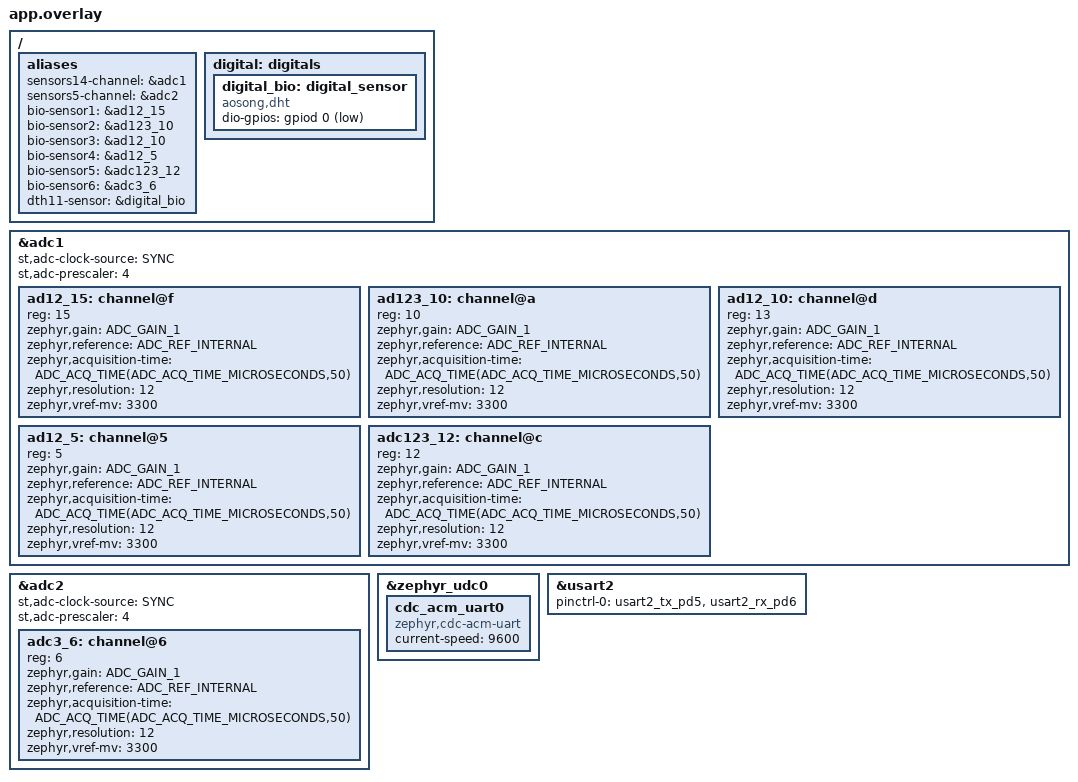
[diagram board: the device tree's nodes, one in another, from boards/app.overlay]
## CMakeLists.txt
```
cmake_minimum_required(VERSION 3.20)

find_package(Zephyr REQUIRED HINTS $ENV{ZEPHYR_BASE})
project(bio_sensors)
target_include_directories(app PUBLIC ${CMAKE_CURRENT_SOURCE_DIR}/lib)
target_sources(app PRIVATE src/main.c src/dth11.c)
```

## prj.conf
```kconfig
CONFIG_ADC=y
CONFIG_GPIO=y
CONFIG_SERIAL=y

CONFIG_CONSOLE=y
CONFIG_PRINTK=y
CONFIG_UART_CONSOLE=y

CONFIG_USB_DEVICE_STACK=y
CONFIG_USB_CDC_ACM=y
CONFIG_USB_DEVICE_INITIALIZE_AT_BOOT=y

CONFIG_ADC_STM32=y

CONFIG_SENSOR=y
CONFIG_DHT=y
```

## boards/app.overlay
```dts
/ {
  aliases {
    sensors14-channel = &adc1;
    sensors5-channel = &adc2;
    bio-sensor1 = &ad12_15;
    bio-sensor2 = &ad123_10;
    bio-sensor3 = &ad12_10;
    bio-sensor4 = &ad12_5;
    bio-sensor5 = &adc123_12;
    bio-sensor6=&adc3_6;
    dth11-sensor= &digital_bio;
  };
  digital: digitals {
    digital_bio: digital_sensor{
      compatible="aosong,dht";
      status="okay";
      dio-gpios=<&gpiod 0 GPIO_ACTIVE_LOW>;
    };
  };
};

&adc1 {
  status="okay";
  #address-cells=<1>;
  #size-cells=<0>;
  st,adc-clock-source = "SYNC";
  st,adc-prescaler=<4>;
  ad12_15: channel@f{
    reg=<15>;
    status="okay";
    zephyr,gain="ADC_GAIN_1";
    zephyr,reference="ADC_REF_INTERNAL";
    zephyr,acquisition-time=<ADC_ACQ_TIME(ADC_ACQ_TIME_MICROSECONDS,50)>;
    zephyr,resolution=<12>;
    zephyr,vref-mv=<3300>;
  };

  ad123_10: channel@a{
    reg=<10>;
    status="okay";
    zephyr,gain="ADC_GAIN_1";
    zephyr,reference="ADC_REF_INTERNAL";
    zephyr,acquisition-time=<ADC_ACQ_TIME(ADC_ACQ_TIME_MICROSECONDS,50)>;
    zephyr,resolution=<12>;
    zephyr,vref-mv=<3300>;
  };

  ad12_10: channel@d{
    reg=<13>;
    status="okay";
    zephyr,gain="ADC_GAIN_1";
    zephyr,reference="ADC_REF_INTERNAL";
    zephyr,acquisition-time=<ADC_ACQ_TIME(ADC_ACQ_TIME_MICROSECONDS,50)>;
    zephyr,resolution=<12>;
    zephyr,vref-mv=<3300>;

  };

  ad12_5: channel@5{
    reg=<5>;
    zephyr,gain="ADC_GAIN_1";
    zephyr,reference="ADC_REF_INTERNAL";
    zephyr,acquisition-time=<ADC_ACQ_TIME(ADC_ACQ_TIME_MICROSECONDS,50)>;
    zephyr,resolution=<12>;
    zephyr,vref-mv=<3300>;

  };
  adc123_12: channel@c{
    reg=<12>;
    zephyr,gain="ADC_GAIN_1";
    zephyr,reference="ADC_REF_INTERNAL";
    zephyr,acquisition-time=<ADC_ACQ_TIME(ADC_ACQ_TIME_MICROSECONDS,50)>;
    zephyr,resolution=<12>;
    zephyr,vref-mv=<3300>;
  };

};

&adc2 {
  status="okay";
  #address-cells=<1>;
  #size-cells=<0>;
  st,adc-clock-source = "SYNC";
  st,adc-prescaler = <4>;
  adc3_6: channel@6{
    reg=<6>;
    zephyr,gain="ADC_GAIN_1";
    zephyr,reference="ADC_REF_INTERNAL";
    zephyr,acquisition-time=<ADC_ACQ_TIME(ADC_ACQ_TIME_MICROSECONDS,50)>;
    zephyr,resolution=<12>;
    zephyr,vref-mv=<3300>;
  };
};
&zephyr_udc0 {
	cdc_acm_uart0: cdc_acm_uart0 {
		compatible = "zephyr,cdc-acm-uart";
		status = "okay";
		current-speed = <9600>;
	};
};
&usart2 {
  status="okay";
  pinctrl-0=<&usart2_tx_pd5 &usart2_rx_pd6>;
  pinctrl-names="default";
};
```

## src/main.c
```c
#include <stdio.h>
#include <zephyr/kernel.h>
#include <zephyr/drivers/gpio.h>
#include <zephyr/drivers/adc.h>
#include <zephyr/device.h>
#include <zephyr/drivers/sensor.h>

#include "dth11.h"

static const int sleep_time_ms =1000;

#define MY_ADC_CHANNEL_1 DT_ALIAS(bio_sensor6)
//#define ADC_CHANNEL_2 DT_ALIAS(sensors5)
struct sensor_value temp,humidity;
static const struct adc_channel_cfg adc_channel_1=ADC_CHANNEL_CFG_DT(MY_ADC_CHANNEL_1);
//static const struct adc_channel_cfg adc_channel_2=ADC_CHANNEL_CFG_DT(ADC_CHANNEL_2);
static const struct device *bio_sen1=DEVICE_DT_GET(DT_ALIAS(sensors14_channel));
//static const struct device *dht_sensor=DEVICE_DT_GET(DT_ALIAS(dth11_sensor));
/*
static const struct device *bio_sen2=DEVICE_DT_GET(DT_ALIAS(bio_sensor2));
static const struct device *bio_sen3=DEVICE_DT_GET(DT_ALIAS(bio_sensor3));
static const struct device *bio_sen4=DEVICE_DT_GET(DT_ALIAS(bio_sensor4));
static const struct device *bio_sen5=DEVICE_DT_GET(DT_ALIAS(bio_sensor5));
*/  

int main(){
  int ret;
  int dht_res;
  uint16_t buf;
  int dth11_data[5];
  uint8_t status;
  uint16_t vref;
  uint8_t vref2;
  int32_t final_voltage;
  vref=DT_PROP(MY_ADC_CHANNEL_1,zephyr_vref_mv);
  //vref2=DT_PROP(ADC_CHANNEL_2,zephyr_vref_mv);  
  struct adc_sequence seq={
    .channels=BIT(adc_channel_1.channel_id),
    .buffer=&buf,
    .buffer_size=sizeof(buf),
    .resolution=DT_PROP(MY_ADC_CHANNEL_1,zephyr_resolution),
  };
  /*
  struct adc_sequence seq2={
    .channels=BIT(adc_channel_2.channel_id),
    .buffer=&buf,
    .buffer_size=sizeof(buf),
    .resolution=DT_PROP(ADC_CHANNEL_2,zephyr_resolution),
  };
  */ 
  
  if(!device_is_ready(bio_sen1)){
    printk("Bio sensor 1 not configured properly \n");
  };
  ret=adc_channel_setup(bio_sen1,&adc_channel_1);
  while(1){
    //int dht_res=sensor_sample_fetch(dht_sensor);
    ret=adc_read(bio_sen1,&seq);
    if(ret<0){
      printk("Error in reading value of sensor 1");
      return 0;
    }
    //printk("%d\n",buf);
    final_voltage=(buf*vref)/((1<<seq.resolution)-1);
    //dht_res=sensor_channel_get(dht_sensor,SENSOR_CHAN_AMBIENT_TEMP,&temp);
    //dht_res=sensor_channel_get(dht_sensor,SENSOR_CHAN_HUMIDITY,&humidity);
    printk("The value read by the Analog sensor is : %u\n",buf);
    printk("The resultant voltage : %u\n",final_voltage);
    //printk("The value read by the dth sensor humidity is : %d.%d\n",temp.val1,temp.val2/1000);
    //printk("The value read by the dht sensor temperature : %d.%d\n",humidity.val1,humidity.val2/1000);

    k_msleep(sleep_time_ms);
  }
  return 0;

}
```

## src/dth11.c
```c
#include <stdio.h>
#include <zephyr/kernel.h>
#include <zephyr/drivers/gpio.h>

int read_sensor_values(struct gpio_dt_spec dev , int data[5]){
  if(!gpio_is_ready_dt(&dev)){
    printk("The sensor is not configured\n");
  }
  int j;
  uint32_t start=0;
  for(int i=0;i<5;i++){
    data[i]=0;
  };
  gpio_pin_configure_dt(&dev,GPIO_OUTPUT);
  gpio_pin_set_dt(&dev,GPIO_OUTPUT_LOW);
  k_msleep(20);
  gpio_pin_set_dt(&dev,GPIO_OUTPUT_HIGH);
  k_busy_wait(30);
  gpio_pin_configure_dt(&dev,GPIO_INPUT | GPIO_PULL_UP);

  start=k_cycle_get_32();
  while(gpio_pin_get_dt(&dev)){
    if (k_cyc_to_us_floor32(k_cycle_get_32() - start) > 100) return -1;
  };
  while(!gpio_pin_get_dt(&dev));
  while (gpio_pin_get_dt(&dev));
  for(int i=0;i<40;i++){
    while(!gpio_pin_get_dt(&dev));
    start=k_cycle_get_32();
    while(gpio_pin_get_dt(&dev));
    uint32_t pulse = k_cyc_to_us_floor32(k_cycle_get_32()-start);
    j=i/8;
    data[j]<<=1;
    if(pulse>50){
      data[j] |=1;
    };
  };
  if (((data[0] + data[1] + data[2] + data[3]) & 0xFF) != data[4]) {
        return -2;
  };
  return 0;

};
```
